VERSION ""

NS_ :

BS_:

BU_: CMC_UNIT

BO_ 100 HANDSHAKE: 16 CMC_UNIT
 SG_ hw_version_major : 0|8@1+ (1,0) [0|255] ""  CMC_UNIT
 SG_ hw_version_minor : 8|8@1+ (1,0) [0|255] ""  CMC_UNIT
 SG_ unit_id : 16|8@1+ (1,0) [0|255] ""  CMC_UNIT
 SG_ unit_type : 24|8@1+ (1,0) [0|255] ""  CMC_UNIT
 SG_ fw_version_major : 32|8@1+ (1,0) [0|255] ""  CMC_UNIT
 SG_ fw_version_minor : 40|8@1+ (1,0) [0|255] ""  CMC_UNIT
 SG_ gc_datetime : 48|32@1+ (1,0) [0|4294967295] ""  CMC_UNIT
 SG_ gc_hash : 80|32@1+ (1,0) [0|4294967295] ""  CMC_UNIT

BO_ 101 HEARTBEAT: 1 CMC_UNIT
 SG_ unit_id : 0|6@1+ (1,0) [0|63] ""  CMC_UNIT
 SG_ system_state : 6|2@1+ (1,0) [0|3] ""  CMC_UNIT

BO_ 202 FEATURE_HORN: 1 CMC_UNIT
 SG_ horn_on : 0|1@1+ (1,0) [0|1] "" Vector__XXX

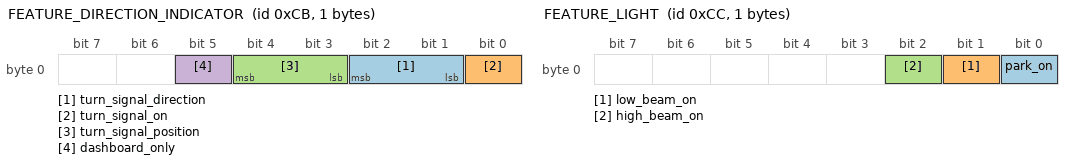
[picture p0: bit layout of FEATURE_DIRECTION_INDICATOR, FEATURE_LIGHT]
BO_ 203 FEATURE_DIRECTION_INDICATOR: 1 CMC_UNIT
 SG_ turn_signal_direction : 1|2@1+ (1,0) [0|2] "" Vector__XXX
 SG_ turn_signal_on : 0|1@1+ (1,0) [0|1] "" Vector__XXX
 SG_ turn_signal_position : 3|2@1+ (1,0) [0|2] "" Vector__XXX
 SG_ dashboard_only : 5|1@1+ (1,0) [0|1] "" Vector__XXX

BO_ 200 FEATURE_IGNITION: 1 CMC_UNIT
 SG_ ignition_on : 0|1@1+ (1,0) [0|1] "" Vector__XXX

BO_ 201 FEATURE_STARTER: 1 CMC_UNIT
 SG_ starter_on : 0|1@1+ (1,0) [0|1] "" Vector__XXX

BO_ 204 FEATURE_LIGHT: 1 CMC_UNIT
 SG_ park_on : 0|1@1+ (1,0) [0|1] "" Vector__XXX
 SG_ low_beam_on : 1|1@1+ (1,0) [0|1] "" Vector__XXX
 SG_ high_beam_on : 2|1@1+ (1,0) [0|1] "" Vector__XXX

BO_ 205 FEATURE_BRAKE_LIGHT: 1 CMC_UNIT
 SG_ brake_light_on : 0|1@1+ (1,0) [0|1] "" Vector__XXX

BO_ 206 FEATURE_NEUTRAL_SENSOR: 1 CMC_UNIT
 SG_ neutral_engaged : 0|1@1+ (1,0) [0|1] "" Vector__XXX

BO_ 207 FEATURE_OIL_PRESSURE_SENSOR: 1 CMC_UNIT
 SG_ oil_pressure_low_detected : 0|1@1+ (1,0) [0|1] "" Vector__XXX

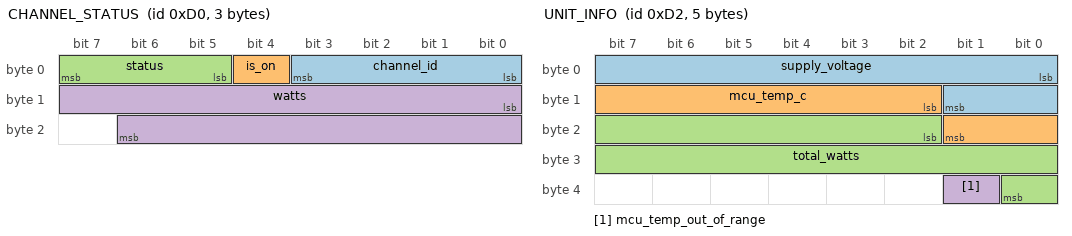
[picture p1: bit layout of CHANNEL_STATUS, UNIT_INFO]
BO_ 208 CHANNEL_STATUS: 3 CMC_UNIT
 SG_ channel_id : 0|4@1+   (1,0)    [0|15]    ""  Vector__XXX
 SG_ is_on      : 4|1@1+   (1,0)    [0|1]     ""  Vector__XXX
 SG_ status     : 5|3@1+   (1,0)    [0|7]     ""  Vector__XXX
 SG_ watts      : 8|15@1+  (0.01,0) [0|200]   "W" Vector__XXX

BO_ 209 CHANNEL_OVERVIEW: 32 CMC_UNIT
 SG_ ch1_is_on   : 0|1@1+    (1,0)    [0|1]   ""  Vector__XXX
 SG_ ch1_status  : 1|3@1+    (1,0)    [0|7]   ""  Vector__XXX
 SG_ ch1_watts   : 4|15@1+   (0.01,0) [0|200] "W" Vector__XXX
 SG_ ch2_is_on   : 19|1@1+   (1,0)    [0|1]   ""  Vector__XXX
 SG_ ch2_status  : 20|3@1+   (1,0)    [0|7]   ""  Vector__XXX
 SG_ ch2_watts   : 23|15@1+  (0.01,0) [0|200] "W" Vector__XXX
 SG_ ch3_is_on   : 38|1@1+   (1,0)    [0|1]   ""  Vector__XXX
 SG_ ch3_status  : 39|3@1+   (1,0)    [0|7]   ""  Vector__XXX
 SG_ ch3_watts   : 42|15@1+  (0.01,0) [0|200] "W" Vector__XXX
 SG_ ch4_is_on   : 57|1@1+   (1,0)    [0|1]   ""  Vector__XXX
 SG_ ch4_status  : 58|3@1+   (1,0)    [0|7]   ""  Vector__XXX
 SG_ ch4_watts   : 61|15@1+  (0.01,0) [0|200] "W" Vector__XXX
 SG_ ch5_is_on   : 76|1@1+   (1,0)    [0|1]   ""  Vector__XXX
 SG_ ch5_status  : 77|3@1+   (1,0)    [0|7]   ""  Vector__XXX
 SG_ ch5_watts   : 80|15@1+  (0.01,0) [0|200] "W" Vector__XXX
 SG_ ch6_is_on   : 95|1@1+   (1,0)    [0|1]   ""  Vector__XXX
 SG_ ch6_status  : 96|3@1+   (1,0)    [0|7]   ""  Vector__XXX
 SG_ ch6_watts   : 99|15@1+  (0.01,0) [0|200] "W" Vector__XXX
 SG_ ch7_is_on   : 114|1@1+  (1,0)    [0|1]   ""  Vector__XXX
 SG_ ch7_status  : 115|3@1+  (1,0)    [0|7]   ""  Vector__XXX
 SG_ ch7_watts   : 118|15@1+ (0.01,0) [0|200] "W" Vector__XXX
 SG_ ch8_is_on   : 133|1@1+  (1,0)    [0|1]   ""  Vector__XXX
 SG_ ch8_status  : 134|3@1+  (1,0)    [0|7]   ""  Vector__XXX
 SG_ ch8_watts   : 137|15@1+ (0.01,0) [0|200] "W" Vector__XXX
 SG_ ch9_is_on   : 152|1@1+  (1,0)    [0|1]   ""  Vector__XXX
 SG_ ch9_status  : 153|3@1+  (1,0)    [0|7]   ""  Vector__XXX
 SG_ ch9_watts   : 156|15@1+ (0.01,0) [0|200] "W" Vector__XXX
 SG_ ch10_is_on  : 171|1@1+  (1,0)    [0|1]   ""  Vector__XXX
 SG_ ch10_status : 172|3@1+  (1,0)    [0|7]   ""  Vector__XXX
 SG_ ch10_watts  : 175|15@1+ (0.01,0) [0|200] "W" Vector__XXX
 SG_ ch11_is_on  : 190|1@1+  (1,0)    [0|1]   ""  Vector__XXX
 SG_ ch11_status : 191|3@1+  (1,0)    [0|7]   ""  Vector__XXX
 SG_ ch11_watts  : 194|15@1+ (0.01,0) [0|200] "W" Vector__XXX
 SG_ ch12_is_on  : 209|1@1+  (1,0)    [0|1]   ""  Vector__XXX
 SG_ ch12_status : 210|3@1+  (1,0)    [0|7]   ""  Vector__XXX
 SG_ ch12_watts  : 213|15@1+ (0.01,0) [0|200] "W" Vector__XXX
 SG_ supply_voltage : 228|10@1+ (0.1,0) [0|102.3] "V" Vector__XXX

BO_ 210 UNIT_INFO: 5 CMC_UNIT
 SG_ supply_voltage          : 0|10@1+  (0.1,0)  [0|102.3]  "V"    Vector__XXX
 SG_ mcu_temp_c              : 10|8@1+  (1,-40)  [-40|215]  "degC" Vector__XXX
 SG_ total_watts             : 18|15@1+ (0.1,0)  [0|3276.7] "W"    Vector__XXX
 SG_ mcu_temp_out_of_range   : 33|1@1+  (1,0)    [0|1]      ""     Vector__XXX

CM_ BO_ 100 "Startup init to check ID and FW for all units, inititate reset or reconfig if needed";
CM_ SG_ 100 hw_version_major "Hardware major version";
CM_ SG_ 100 hw_version_minor "Hardware minor version";
CM_ SG_ 100 unit_id "Unique ID for the source unit";
CM_ SG_ 100 unit_type "Unit type";
CM_ SG_ 100 fw_version_major "Firmware major version, should listed for compability to ensure units can be combined";
CM_ SG_ 100 fw_version_minor "Firmware minor version, for info only";
CM_ SG_ 100 gc_datetime "All global configs across all units must be the same, datetime is when the config was created/updated, if not the same across units or if missing, the most recent updated config is to be used and passed over to units with old config";
CM_ SG_ 100 gc_hash "All global configs across all units must be the same, this hash represent global config checksum";
CM_ BO_ 101 "Poll on system frequently to identify missing units or mishaps";
CM_ SG_ 101 unit_id "Unique ID for the source unit";
CM_ SG_ 101 system_state "Report system state for taking action if not OK";
CM_ BO_ 202 "Turn horn on/off";
CM_ SG_ 202 horn_on "0=off, 1=on";
CM_ BO_ 203 "Turn direction indicators on/off, send also info for left, righ or both (hazard) and optionally if to be turned of only for front or rear, normally should be both. Separate for turning on indicator only, to be used for startup animation or check that dashboard indicator bulb works";
CM_ SG_ 203 turn_signal_direction "0=left, 1=right, 2=both";
CM_ SG_ 203 turn_signal_on "0=off, 1=on";
CM_ SG_ 203 turn_signal_position "0=front, 1=rear, 2=both";
CM_ SG_ 203 dashboard_only "0=normal operation, 1=only affect dashboard warning indicator";
CM_ BO_ 200 "Control ignition status";
CM_ SG_ 200 ignition_on "0=off, 1=on";
CM_ BO_ 201 "Control starter motor";
CM_ SG_ 201 starter_on "0=off, 1=engaged (on)";
CM_ BO_ 204 "Lights: park, low beam and high beam";
CM_ SG_ 204 park_on "0 = off, 1=on";
CM_ SG_ 204 low_beam_on "0 = off, 1=on";
CM_ SG_ 204 high_beam_on "0 = off, 1=on";
CM_ BO_ 205 "Lights: Brake Light";
CM_ SG_ 205 brake_light_on "0 = off, 1 = on";
CM_ BO_ 206 "Neutral sensor should activate dashboard light";
CM_ SG_ 206 neutral_engaged "0 = off, 1 = on";
CM_ BO_ 207 "Oil Pressure Sensor should activate warning light on dash";
CM_ SG_ 207 oil_pressure_low_detected "0 = normal operation, 1 = low pressure detected";
CM_ BO_ 208 "Per-channel status; sent once per configured channel per second and immediately on status change";
CM_ SG_ 208 channel_id "Logical output channel number (0-based)";
CM_ SG_ 208 is_on "1 = switch is currently driven on";
CM_ SG_ 208 status "Channel status code (see VAL_ table)";
CM_ SG_ 208 watts "Power consumption in Watts";
CM_ BO_ 209 "Overview of all 12 channel slots sent every 1 s when overview_enabled=1 in config; unused slots are zero; CAN FD frame";
CM_ BO_ 210 "Unit-level telemetry sent every 1 s: supply voltage, MCU die temperature, and total power across all active channels";
CM_ SG_ 210 supply_voltage "Switch supply voltage in V; default 12.0 V until sensing HW is added";
CM_ SG_ 210 mcu_temp_c "STM32G4 die temperature in degC; show N/A to user when mcu_temp_out_of_range = 1";
CM_ SG_ 210 total_watts "Sum of watts across all active output channels";
CM_ SG_ 210 mcu_temp_out_of_range "1 = temperature reading is out of valid range; display N/A instead of mcu_temp_c";
BA_DEF_  "BusType" STRING ;
BA_DEF_ BO_  "CANFD_BRS" ENUM  "0","1";
BA_DEF_ BO_  "GenMsgCycleTime" INT 0 10000;
BA_DEF_ BO_  "VFrameFormat" ENUM  "StandardCAN","ExtendedCAN","reserved","reserved","reserved","reserved","reserved","reserved","reserved","reserved","reserved","reserved","reserved","reserved","StandardCAN_FD","ExtendedCAN_FD";
BA_DEF_DEF_  "BusType" "";
BA_DEF_DEF_  "CANFD_BRS" "0";
BA_DEF_DEF_  "GenMsgCycleTime" 0;
BA_DEF_DEF_  "VFrameFormat" "StandardCAN";
BA_ "BusType" "CAN FD";
BA_ "VFrameFormat" BO_ 100 14;
BA_ "CANFD_BRS" BO_ 100 1;
BA_ "VFrameFormat" BO_ 209 14;
BA_ "CANFD_BRS" BO_ 209 1;
BA_ "GenMsgCycleTime" BO_ 208 1000;
BA_ "GenMsgCycleTime" BO_ 209 1000;
BA_ "GenMsgCycleTime" BO_ 210 1000;
VAL_ 100 unit_type 0 "UNKNOWN" 1 "I/O UNIT" ;
VAL_ 101 system_state 0 "UNKNOWN" 1 "OK" 2 "WARNING" 3 "FAULT" ;
VAL_ 208 status       0 "POWER_GOOD" 1 "OPEN_LOAD" 2 "OVERCURRENT" 3 "OVERTEMP" 4 "SHORT_VS" ;
VAL_ 209 ch1_status   0 "POWER_GOOD" 1 "OPEN_LOAD" 2 "OVERCURRENT" 3 "OVERTEMP" 4 "SHORT_VS" ;
VAL_ 209 ch2_status   0 "POWER_GOOD" 1 "OPEN_LOAD" 2 "OVERCURRENT" 3 "OVERTEMP" 4 "SHORT_VS" ;
VAL_ 209 ch3_status   0 "POWER_GOOD" 1 "OPEN_LOAD" 2 "OVERCURRENT" 3 "OVERTEMP" 4 "SHORT_VS" ;
VAL_ 209 ch4_status   0 "POWER_GOOD" 1 "OPEN_LOAD" 2 "OVERCURRENT" 3 "OVERTEMP" 4 "SHORT_VS" ;
VAL_ 209 ch5_status   0 "POWER_GOOD" 1 "OPEN_LOAD" 2 "OVERCURRENT" 3 "OVERTEMP" 4 "SHORT_VS" ;
VAL_ 209 ch6_status   0 "POWER_GOOD" 1 "OPEN_LOAD" 2 "OVERCURRENT" 3 "OVERTEMP" 4 "SHORT_VS" ;
VAL_ 209 ch7_status   0 "POWER_GOOD" 1 "OPEN_LOAD" 2 "OVERCURRENT" 3 "OVERTEMP" 4 "SHORT_VS" ;
VAL_ 209 ch8_status   0 "POWER_GOOD" 1 "OPEN_LOAD" 2 "OVERCURRENT" 3 "OVERTEMP" 4 "SHORT_VS" ;
VAL_ 209 ch9_status   0 "POWER_GOOD" 1 "OPEN_LOAD" 2 "OVERCURRENT" 3 "OVERTEMP" 4 "SHORT_VS" ;
VAL_ 209 ch10_status  0 "POWER_GOOD" 1 "OPEN_LOAD" 2 "OVERCURRENT" 3 "OVERTEMP" 4 "SHORT_VS" ;
VAL_ 209 ch11_status  0 "POWER_GOOD" 1 "OPEN_LOAD" 2 "OVERCURRENT" 3 "OVERTEMP" 4 "SHORT_VS" ;
VAL_ 209 ch12_status  0 "POWER_GOOD" 1 "OPEN_LOAD" 2 "OVERCURRENT" 3 "OVERTEMP" 4 "SHORT_VS" ;
